VERSION ""

NS_ :

BS_:

BU_: XXX

BO_ 85 CID_ELOTFF: 8 XXX
 SG_ sig_ybrcex : 40|1@1+ (1,0) [0|1] "" XXX
 SG_ sig_qqsmrd : 56|8@1+ (1,0) [0|255] "" XXX

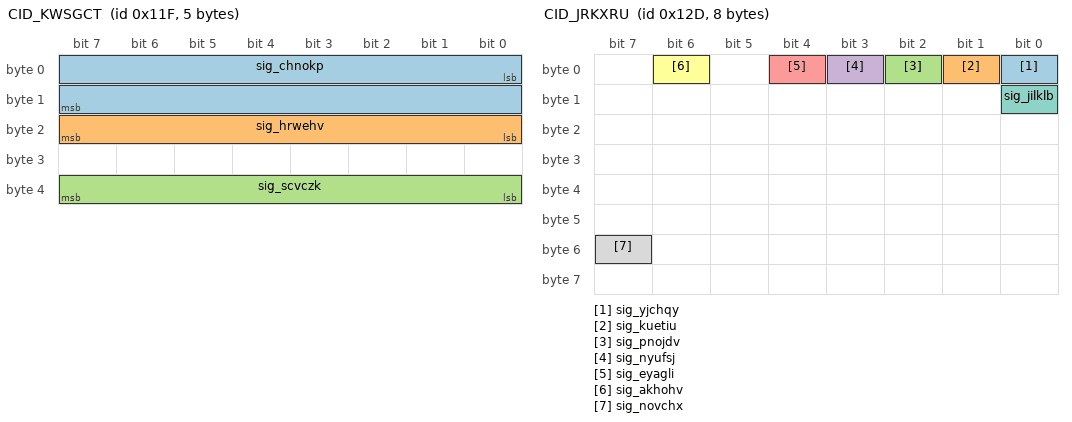
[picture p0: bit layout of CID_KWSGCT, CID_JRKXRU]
BO_ 287 CID_KWSGCT: 5 XXX
 SG_ sig_chnokp : 0|16@1- (0.1,0) [-450|450] "" XXX
 SG_ sig_hrwehv : 16|8@1+ (4,0) [0|1020] "" XXX
 SG_ sig_scvczk : 32|8@1+ (1,0) [0|255] "" XXX

BO_ 289 CID_VVFMPU: 8 XXX
 SG_ sig_tsihtg : 0|12@1+ (1,0) [0|255] "" XXX

BO_ 301 CID_JRKXRU: 8 XXX
 SG_ sig_yjchqy : 0|1@0+ (1,0) [0|1] "" XXX
 SG_ sig_kuetiu : 1|1@0+ (1,0) [0|1] "" XXX
 SG_ sig_pnojdv : 2|1@0+ (1,0) [0|1] "" XXX
 SG_ sig_nyufsj : 3|1@0+ (1,0) [0|1] "" XXX
 SG_ sig_eyagli : 4|1@0+ (1,0) [0|1] "" XXX
 SG_ sig_akhohv : 6|1@0+ (1,0) [0|1] "" XXX
 SG_ sig_jilklb : 8|1@0+ (1,0) [0|1] "" XXX
 SG_ sig_novchx : 55|1@0+ (1,0) [0|1] "" XXX

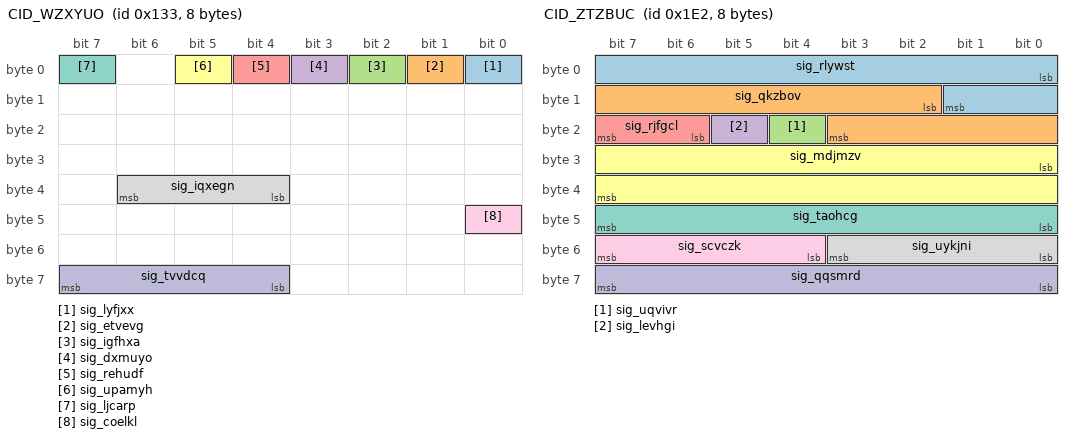
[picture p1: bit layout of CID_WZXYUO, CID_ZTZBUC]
BO_ 307 CID_WZXYUO: 8 XXX
 SG_ sig_lyfjxx : 0|1@0+ (1,0) [0|1] "" XXX
 SG_ sig_etvevg : 1|1@1+ (1,0) [0|1] "" XXX
 SG_ sig_igfhxa : 2|1@1+ (1,0) [0|1] "" XXX
 SG_ sig_dxmuyo : 3|1@1+ (1,0) [0|1] "" XXX
 SG_ sig_rehudf : 4|1@0+ (1,0) [0|1] "" XXX
 SG_ sig_upamyh : 5|1@0+ (1,0) [0|1] "" XXX
 SG_ sig_ljcarp : 7|1@0+ (1,0) [0|1] "" XXX
 SG_ sig_iqxegn : 36|3@1+ (1,0) [0|7] "" XXX
 SG_ sig_coelkl : 40|1@0+ (1,0) [0|1] "" XXX
 SG_ sig_tvvdcq : 63|4@0+ (1,0) [0|15] "" XXX

BO_ 482 CID_ZTZBUC: 8 XXX
 SG_ sig_rlywst : 0|10@1- (0.01,0) [0|5] "" XXX
 SG_ sig_qkzbov : 10|10@1- (0.01,0) [-5|0] "" XXX
 SG_ sig_uqvivr : 20|1@0+ (1,0) [0|1] "" XXX
 SG_ sig_levhgi : 21|1@0+ (1,0) [0|1] "" XXX
 SG_ sig_rjfgcl : 22|2@1+ (1,0) [0|1] "" XXX
 SG_ sig_mdjmzv : 24|16@1- (0.1,0) [-780|779.9] "" XXX
 SG_ sig_taohcg : 47|8@0+ (1,0) [0|255] "" XXX
 SG_ sig_uykjni : 48|4@1+ (1,0) [0|15] "" XXX
 SG_ sig_scvczk : 52|4@1+ (1,0) [0|15] "" XXX
 SG_ sig_qqsmrd : 56|8@1+ (1,0) [0|255] "" XXX

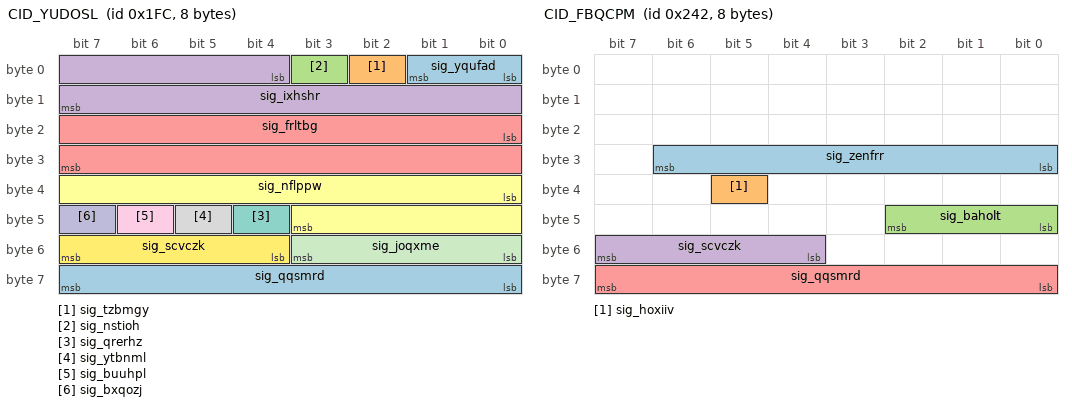
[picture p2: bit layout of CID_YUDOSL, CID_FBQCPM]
BO_ 508 CID_YUDOSL: 8 XXX
 SG_ sig_yqufad : 0|2@1+ (1,0) [0|1] "" XXX
 SG_ sig_tzbmgy : 2|1@1+ (1,0) [0|1] "" XXX
 SG_ sig_nstioh : 3|1@0+ (1,0) [0|1] "" XXX
 SG_ sig_ixhshr : 4|12@1- (1,0) [-2048|2047] "" XXX
 SG_ sig_frltbg : 16|16@1- (0.1,0) [-780|779.9] "Deg" XXX
 SG_ sig_nflppw : 32|12@1- (1,0) [0|63] "" XXX
 SG_ sig_qrerhz : 44|1@0+ (1,0) [0|1] "" XXX
 SG_ sig_ytbnml : 45|1@1+ (1,0) [0|255] "" XXX
 SG_ sig_buuhpl : 46|1@1+ (1,0) [0|1] "" XXX
 SG_ sig_bxqozj : 47|1@0+ (1,0) [0|3] "" XXX
 SG_ sig_joqxme : 48|4@1+ (1,0) [0|15] "" XXX
 SG_ sig_scvczk : 52|4@1+ (1,0) [0|15] "" XXX
 SG_ sig_qqsmrd : 56|8@1+ (1,0) [0|255] "" XXX

BO_ 578 CID_FBQCPM: 8 XXX
 SG_ sig_zenfrr : 30|7@0+ (1,0) [0|127] "" XXX
 SG_ sig_hoxiiv : 37|1@0+ (1,0) [0|1] "" XXX
 SG_ sig_baholt : 40|3@1+ (1,0) [0|7] "" XXX
 SG_ sig_scvczk : 55|4@0+ (1,0) [0|15] "" XXX
 SG_ sig_qqsmrd : 56|8@1+ (1,0) [0|255] "" XXX

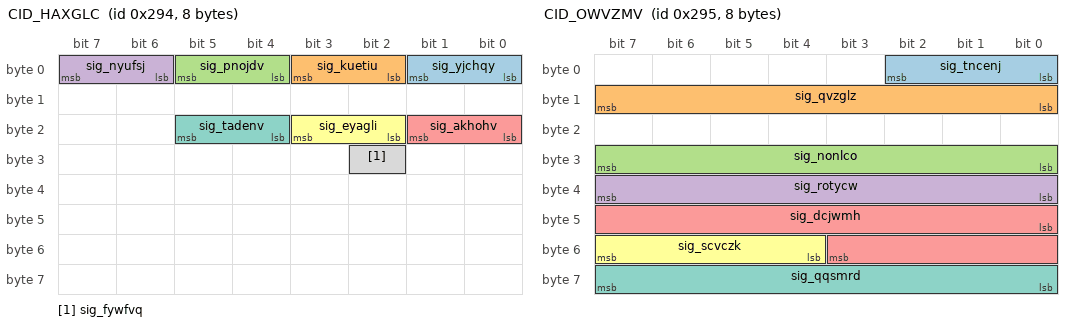
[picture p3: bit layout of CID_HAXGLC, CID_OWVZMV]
BO_ 660 CID_HAXGLC: 8 XXX
 SG_ sig_yjchqy : 1|2@0+ (1,0) [0|3] "" XXX
 SG_ sig_kuetiu : 3|2@0+ (1,0) [0|3] "" XXX
 SG_ sig_pnojdv : 5|2@0+ (1,0) [0|3] "" XXX
 SG_ sig_nyufsj : 7|2@0+ (1,0) [0|3] "" XXX
 SG_ sig_akhohv : 17|2@0+ (1,0) [0|3] "" XXX
 SG_ sig_eyagli : 19|2@0+ (1,0) [0|3] "" XXX
 SG_ sig_tadenv : 21|2@0+ (1,0) [0|3] "" XXX
 SG_ sig_fywfvq : 26|1@0+ (1,0) [0|1] "" XXX

BO_ 661 CID_OWVZMV: 8 XXX
 SG_ sig_tncenj : 2|3@0+ (1,0) [0|7] "" XXX
 SG_ sig_qvzglz : 15|8@0+ (1,0) [0|255] "" XXX
 SG_ sig_nonlco : 31|8@0+ (1,0) [0|255] "" XXX
 SG_ sig_rotycw : 32|8@1+ (1,0) [0|255] "" XXX
 SG_ sig_dcjwmh : 40|12@1+ (1,0) [0|255] "" XXX
 SG_ sig_scvczk : 52|4@1+ (1,0) [0|15] "" XXX
 SG_ sig_qqsmrd : 63|8@0+ (1,0) [0|255] "" XXX

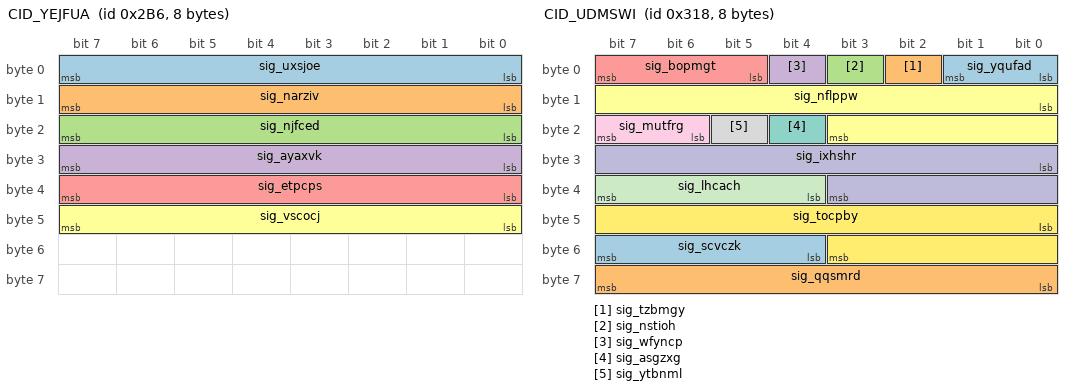
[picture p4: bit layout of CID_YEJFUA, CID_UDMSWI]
BO_ 694 CID_YEJFUA: 8 XXX
 SG_ sig_uxsjoe : 7|8@0+ (1,0) [0|255] "" XXX
 SG_ sig_narziv : 15|8@0+ (1,0) [0|255] "" XXX
 SG_ sig_njfced : 23|8@0+ (1,0) [0|255] "" XXX
 SG_ sig_ayaxvk : 31|8@0+ (1,0) [0|255] "" XXX
 SG_ sig_etpcps : 39|8@0+ (1,0) [0|255] "" XXX
 SG_ sig_vscocj : 47|8@0+ (1,0) [0|255] "" XXX

BO_ 790 CID_JBNXEW: 8 XXX
 SG_ sig_fnermm : 3|4@0+ (1,0) [0|1] "" XXX
 SG_ sig_jwvyzg : 4|2@1+ (1,0) [0|3] "" XXX
 SG_ sig_kgdnoa : 6|2@1+ (1,0) [0|3] "" XXX
 SG_ sig_jpblgl : 8|2@1+ (1,0) [0|3] "" XXX
 SG_ sig_bllbco : 10|1@1+ (1,0) [0|1] "" XXX
 SG_ sig_asokzl : 11|4@1+ (1,0) [0|1] "" XXX
 SG_ sig_wpgelx : 15|1@0+ (1,0) [0|1] "" XXX
 SG_ sig_mdjmzv : 16|11@1- (1,0) [-1024|1023] "" XXX
 SG_ sig_uqvivr : 27|1@1+ (1,0) [0|1] "" XXX
 SG_ sig_levhgi : 28|1@1+ (1,0) [0|3] "" XXX
 SG_ sig_bvlatn : 29|1@0+ (1,0) [0|1] "" XXX
 SG_ sig_lidgna : 30|1@0+ (1,0) [0|1] "" XXX
 SG_ sig_fvgeua : 31|1@0+ (1,0) [0|1] "" XXX
 SG_ sig_moqdei : 32|2@1+ (1,0) [0|3] "" XXX
 SG_ sig_hmlvua : 34|2@1+ (1,0) [0|3] "" XXX
 SG_ sig_ibimkh : 36|4@1+ (1,0) [0|3] "" XXX
 SG_ sig_eqqntt : 40|8@1+ (5,-5) [-5|1270] "" XXX
 SG_ sig_vzuprm : 49|2@0+ (1,0) [0|3] "" XXX
 SG_ sig_lmwive : 51|2@0+ (1,0) [0|3] "" XXX
 SG_ sig_scvczk : 52|4@1+ (1,0) [0|15] "" XXX
 SG_ sig_qqsmrd : 56|8@1+ (1,0) [0|15] "" XXX

BO_ 792 CID_UDMSWI: 8 XXX
 SG_ sig_yqufad : 0|2@1+ (1,0) [0|1] "" XXX
 SG_ sig_tzbmgy : 2|1@1+ (1,0) [0|1] "" XXX
 SG_ sig_nstioh : 3|1@1+ (1,0) [0|1] "" XXX
 SG_ sig_wfyncp : 4|1@1+ (1,0) [0|1] "" XXX
 SG_ sig_bopmgt : 5|3@1+ (1,0) [0|1] "" XXX
 SG_ sig_nflppw : 8|12@1- (1,0) [-2048|2047] "" XXX
 SG_ sig_asgzxg : 20|1@1+ (1,0) [0|1] "" XXX
 SG_ sig_ytbnml : 21|1@1+ (1,0) [0|1] "" XXX
 SG_ sig_mutfrg : 22|2@1+ (1,0) [0|15] "" XXX
 SG_ sig_ixhshr : 24|12@1- (1,0) [-2048|2047] "" XXX
 SG_ sig_lhcach : 36|4@1+ (1,0) [0|15] "" XXX
 SG_ sig_tocpby : 40|12@1+ (1,0) [0|4095] "" XXX
 SG_ sig_scvczk : 52|4@1+ (1,0) [0|15] "" XXX
 SG_ sig_qqsmrd : 56|8@1+ (1,0) [0|255] "" XXX

BO_ 813 CID_UJWUWJ: 8 XXX
 SG_ sig_jitylk : 0|9@1+ (0.5,0) [0|255.5] "" XXX
 SG_ sig_hkkshm : 9|1@1+ (1,0) [0|1] "" XXX
 SG_ sig_lhgtfy : 10|3@1+ (1,0) [0|7] "" XXX
 SG_ sig_vnipvs : 13|3@1+ (1,0) [0|7] "" XXX
 SG_ sig_pzjhta : 16|1@1+ (1,0) [0|1] "" XXX
 SG_ sig_homujv : 17|1@1+ (1,0) [0|1] "" XXX
 SG_ sig_nstioh : 18|1@1+ (1,0) [0|1] "" XXX
 SG_ sig_pdmtad : 19|3@1+ (1,0) [0|1] "" XXX
 SG_ sig_lbifiw : 22|1@0+ (1,0) [0|1] "" XXX
 SG_ sig_ndvwtr : 23|1@0+ (1,0) [0|1] "" XXX
 SG_ sig_jpblgl : 24|1@1+ (1,0) [0|1] "" XXX
 SG_ sig_jfwuja : 25|7@1+ (1,0) [0|127] "" XXX
 SG_ sig_kartba : 32|4@1+ (1,0) [0|15] "" XXX
 SG_ sig_qgnjme : 36|12@1+ (1,0) [0|4095] "" XXX
 SG_ sig_scvczk : 48|4@1+ (1,0) [0|15] "" XXX
 SG_ sig_khqxnc : 55|4@0+ (1,0) [0|15] "" XXX
 SG_ sig_qqsmrd : 56|8@1+ (1,0) [0|255] "" XXX

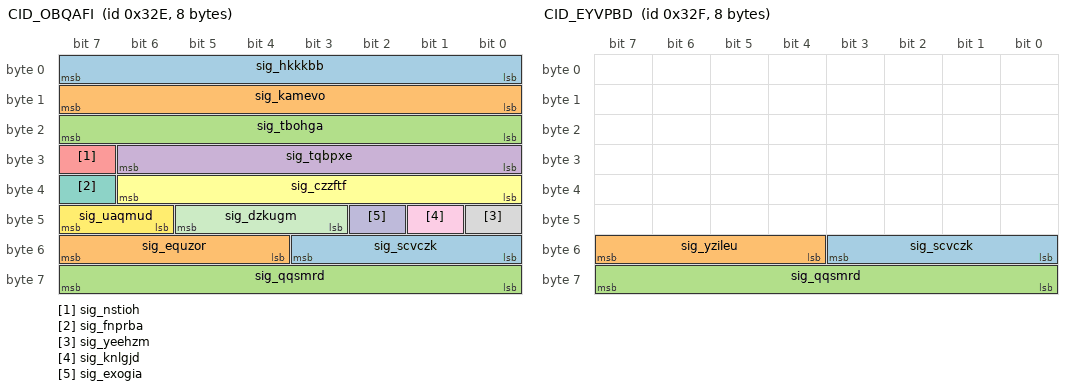
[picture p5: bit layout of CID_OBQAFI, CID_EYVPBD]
BO_ 814 CID_OBQAFI: 8 XXX
 SG_ sig_hkkkbb : 0|8@1+ (0.05,-5) [-100|155] "" XXX
 SG_ sig_kamevo : 8|8@1+ (0.05,-5) [0|1.26] "" XXX
 SG_ sig_tbohga : 16|8@1+ (0.05,-5) [0|1.26] "" XXX
 SG_ sig_tqbpxe : 24|7@1+ (0.2,0) [0|12.7] "" XXX
 SG_ sig_nstioh : 31|1@0+ (1,0) [0|1] "" XXX
 SG_ sig_czzftf : 32|7@1+ (0.2,-16) [0|12.7] "" XXX
 SG_ sig_fnprba : 39|1@0+ (1,0) [0|1] "" XXX
 SG_ sig_yeehzm : 40|1@0+ (1,0) [0|1] "" XXX
 SG_ sig_knlgjd : 41|1@0+ (1,0) [0|1] "" XXX
 SG_ sig_exogia : 42|1@1+ (1,0) [0|3] "" XXX
 SG_ sig_dzkugm : 45|3@0+ (1,0) [0|1] "" XXX
 SG_ sig_uaqmud : 46|2@1+ (1,0) [0|3] "" XXX
 SG_ sig_scvczk : 48|4@1+ (1,0) [0|15] "" XXX
 SG_ sig_equzor : 55|4@0+ (1,0) [0|15] "" XXX
 SG_ sig_qqsmrd : 56|8@1+ (1,0) [0|255] "" XXX

BO_ 815 CID_EYVPBD: 8 XXX
 SG_ sig_scvczk : 48|4@1+ (1,0) [0|15] "" XXX
 SG_ sig_yzileu : 55|4@0+ (1,0) [0|15] "" XXX
 SG_ sig_qqsmrd : 56|8@1+ (1,0) [0|255] "" XXX

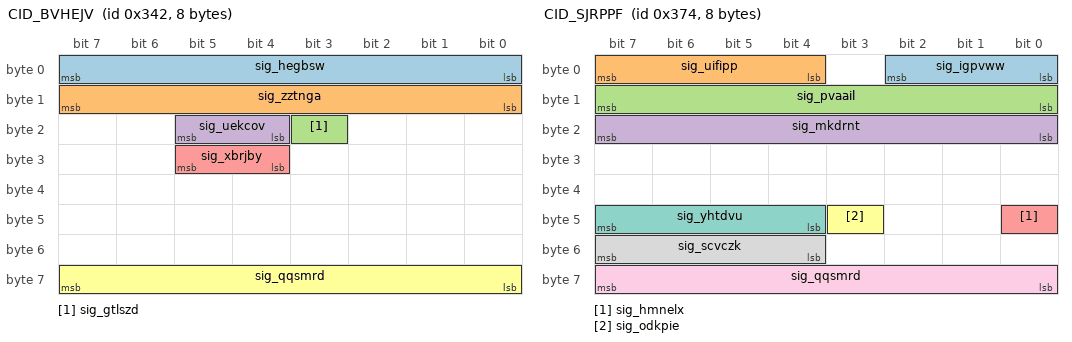
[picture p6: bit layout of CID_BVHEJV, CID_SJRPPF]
BO_ 834 CID_BVHEJV: 8 XXX
 SG_ sig_hegbsw : 0|8@1+ (0.01,0) [0|2.55] "" XXX
 SG_ sig_zztnga : 8|8@1+ (0.01,0) [0|2.55] "" XXX
 SG_ sig_gtlszd : 19|1@1+ (1,0) [0|1] "" XXX
 SG_ sig_uekcov : 20|2@1+ (1,0) [0|255] "" XXX
 SG_ sig_xbrjby : 28|2@1+ (1,0) [0|1] "" XXX
 SG_ sig_qqsmrd : 56|8@1+ (1,0) [0|255] "" XXX

BO_ 884 CID_SJRPPF: 8 MRR
 SG_ sig_igpvww : 2|3@0+ (1,0) [0|3] "" MRR
 SG_ sig_uifipp : 7|4@0+ (1,0) [0|15] "" MRR
 SG_ sig_pvaail : 15|8@0+ (0.1,-12) [0|255] "" MRR
 SG_ sig_mkdrnt : 23|8@0+ (1,-100) [0|255] "" MRR
 SG_ sig_hmnelx : 40|1@0+ (1,0) [0|3] "" MRR
 SG_ sig_odkpie : 43|1@0+ (1,0) [0|1] "" XXX
 SG_ sig_yhtdvu : 44|4@1+ (1,0) [0|15] "" XXX
 SG_ sig_scvczk : 52|4@1+ (1,0) [0|15] "" MRR
 SG_ sig_qqsmrd : 56|8@1+ (1,0) [0|255] "" MRR

BO_ 944 CID_SXUUHD: 8 XXX
 SG_ sig_anhcia : 1|2@0+ (1,0) [0|3] "" XXX
 SG_ sig_scgphi : 2|1@0+ (1,0) [0|1] "" XXX
 SG_ sig_amljab : 4|2@0+ (1,0) [0|3] "" XXX
 SG_ sig_cjlqfg : 5|1@0+ (1,0) [0|1] "" XXX
 SG_ sig_czlrqi : 6|1@0+ (1,0) [0|1] "" XXX
 SG_ sig_snnqev : 7|1@0+ (1,0) [0|1] "" XXX
 SG_ sig_pdowzm : 8|1@0+ (1,0) [0|1] "" XXX
 SG_ sig_ugjuzx : 11|3@0+ (1,0) [0|7] "" XXX
 SG_ sig_lpxdkg : 12|1@0+ (1,0) [0|1] "" XXX
 SG_ sig_qvlhrw : 14|2@0+ (1,0) [0|3] "" XXX
 SG_ sig_dfjggd : 15|1@0+ (1,0) [0|1] "" XXX
 SG_ sig_lmcdsm : 16|1@0+ (1,0) [0|1] "" XXX
 SG_ sig_geykpx : 18|2@0+ (1,0) [0|3] "" XXX
 SG_ sig_bwchdc : 19|1@0+ (1,0) [0|1] "" XXX
 SG_ sig_nwjjtu : 23|4@0+ (1,0) [0|15] "" XXX
 SG_ sig_ragngx : 24|28@1+ (1,0) [0|268435455] "" XXX
 SG_ sig_scvczk : 52|4@1+ (1,0) [0|15] "" XXX
 SG_ sig_qqsmrd : 56|8@1+ (1,0) [0|255] "" XXX

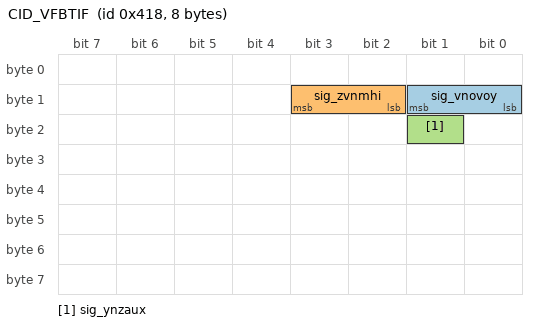
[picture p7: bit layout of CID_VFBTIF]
BO_ 1048 CID_VFBTIF: 8 XXX
 SG_ sig_vnovoy : 9|2@0+ (1,0) [0|1] "" XXX
 SG_ sig_zvnmhi : 11|2@0+ (1,0) [0|1] "" XXX
 SG_ sig_ynzaux : 17|1@0+ (1,0) [0|1] "" XXX

VAL_ 578 sig_baholt 4 "D" 2 "R" 3 "N" 1 "P";
VAL_ 790 sig_fnermm 11 "AutoFullBeamActive" 2 "AutoFullBeamInactive";
VAL_ 790 sig_jwvyzg 0 "GRAY" 1 "GREEN" 2 "YELLOW" 3 "RED";
VAL_ 790 sig_kgdnoa 3 "ALARM_AND_LKA" 2 "LKA" 1 "ALARM" 0 "DISABLE";
VAL_ 790 sig_hmlvua 0 "GRAY" 1 "GREEN" 2 "YELLOW" 3 "RED";
VAL_ 790 sig_vzuprm 0 "VIBRATION" 1 "AUDIO" 2 "AUDIO_AND_VIBRATION";
VAL_ 792 sig_yqufad 0 "NotReady" 1 "Ready" 2 "Active" 3 "TemporaryFail";
VAL_ 813 sig_lhgtfy 4 "4BAR" 3 "3BAR" 2 "2BAR" 1 "1BAR";
VAL_ 813 sig_pdmtad 0 "OFF" 2 "ACC_ON" 3 "ACC_ACTIVE" 5 "FORCE_ACCEL" 7 "ERROR";
VAL_ 813 sig_jfwuja 36 "ACC_ERROR" 22 "OVERRIDE" 12 "ENGAGE" 8 "DISENGAGE" 20 "ACC_ON" 32 "ACC_OFF" 48 "CHECK_GEAR_D" 16 "FORCE_ACCEL" 0 "NONE";
VAL_ 814 sig_dzkugm 0 "Off" 1 "Passive" 2 "StandBy" 3 "ActiveControl" 4 "BrakeOnly" 5 "Override" 6 "Standstill" 7 "Failure";
VAL_ 814 sig_uaqmud 0 "Softoff" 1 "Fastoff" 2 "Immediateoff" 3 "Initial";
VAL_ 834 sig_uekcov 2 "SPORT" 1 "ECO" 0 "SNOW";
VAL_ 834 sig_xbrjby 3 "HEV" 2 "FORCE_EV" 1 "EV";
VAL_ 944 sig_amljab 0 "NOTPRESSED" 1 "DOWN_SETSPEED" 3 "UP_RESETSPEED";
